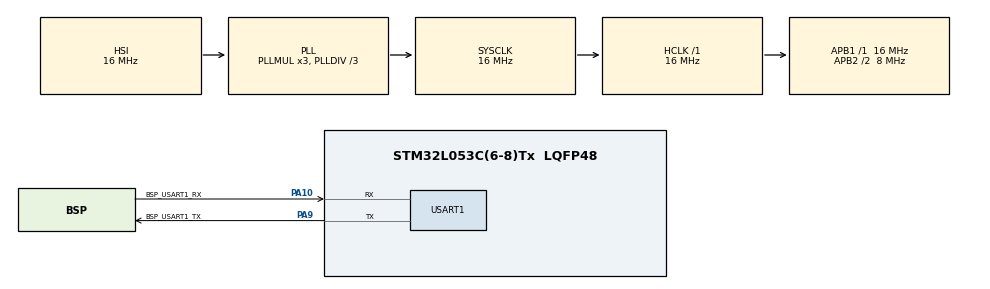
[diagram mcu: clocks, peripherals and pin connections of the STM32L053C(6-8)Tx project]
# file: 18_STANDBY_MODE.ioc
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Mcu.Family=STM32L0
Mcu.Name=STM32L053C(6-8)Tx
Mcu.Package=LQFP48
PA0.GPIO_Label=BSP_SYS_WKUP1
PA0.Mode=SYS_WakeUp0
PA0.Signal=SYS_WKUP1
PA10.GPIO_Label=BSP_USART1_RX
PA10.Mode=Asynchronous
PA10.Signal=USART1_RX
PA9.GPIO_Label=BSP_USART1_TX
PA9.Mode=Asynchronous
PA9.Signal=USART1_TX
ProjectManager.HeapSize=0x200
ProjectManager.StackSize=0x400
ProjectManager.TargetToolchain=STM32CubeIDE
RCC.AHBFreq_Value=16000000
RCC.APB1Freq_Value=16000000
RCC.APB1TimFreq_Value=16000000
RCC.APB2CLKDivider=RCC_HCLK_DIV2
RCC.APB2Freq_Value=8000000
RCC.APB2TimFreq_Value=16000000
RCC.HCLKFreq_Value=16000000
RCC.HSE_VALUE=8000000
RCC.HSI16_VALUE=16000000
RCC.HSI48MClockSelection=RCC_USBCLKSOURCE_HSI48
RCC.HSI48_VALUE=48000000
RCC.HSI_VALUE=16000000
RCC.LSE_VALUE=32768
RCC.MSI_VALUE=2097000
RCC.PLLDIV=RCC_PLLDIV_3
RCC.RTCClockSelection=RCC_RTCCLKSOURCE_LSI
RCC.RTCClockSelectionVirtual=RCC_RTCCLKSOURCE_LSE
RCC.SYSCLKFreq_VALUE=16000000
RCC.SYSCLKSource=RCC_SYSCLKSOURCE_PLLCLK
RCC.VCOOutputFreq_Value=48000000
USART1.VirtualMode-Asynchronous=VM_ASYNC
VP_RTC_VS_RTC_Activate.Mode=RTC_Enabled
VP_RTC_VS_RTC_WakeUp_intern.Mode=WakeUp
board=STM32L0538-DISCO

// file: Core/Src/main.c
/* USER CODE BEGIN Header */
/**
 ******************************************************************************
 * @file           : main.c
 * @brief          : Main program body
 ******************************************************************************
 * @attention
 *
 * Copyright (c) 2024 STMicroelectronics.
 * All rights reserved.
 *
 * This software is licensed under terms that can be found in the LICENSE file
 * in the root directory of this software component.
 * If no LICENSE file comes with this software, it is provided AS-IS.
 *
 ******************************************************************************
 */
/* USER CODE END Header */
#include "main.h"

/* USER CODE BEGIN Includes */
#include <string.h>
/* USER CODE END Includes */

RTC_HandleTypeDef hrtc;

UART_HandleTypeDef huart1;

/* USER CODE BEGIN PV */
int i;
/* USER CODE END PV */

void SystemClock_Config(void);
static void MX_GPIO_Init(void);
static void MX_USART1_UART_Init(void);
static void MX_RTC_Init(void);

int main(void)
{

  /* MCU Configuration--------------------------------------------------------*/

  /* Reset of all peripherals, Initializes the Flash interface and the Systick. */
  HAL_Init();

  /* Configure the system clock */
  SystemClock_Config();

  /* Initialize all configured peripherals */
  MX_GPIO_Init();
  MX_USART1_UART_Init();
  MX_RTC_Init();
  /* USER CODE BEGIN 2 */

	/* check if the SB flag is set */
	if (__HAL_PWR_GET_FLAG(PWR_FLAG_SB) != RESET) {
		__HAL_PWR_CLEAR_FLAG(PWR_FLAG_SB);		// clear the flag

		/* display the string */
		char *str = "Wake-up from the standby mode\r\n";
		HAL_UART_Transmit(&huart1, (uint8_t*) str, strlen(str), HAL_MAX_DELAY);

		/* blink led */
//		for (i = 0; i < 20; i++) {
//			HAL_GPIO_TogglePin(GPIOA, GPIO_PIN_5);
//			HAL_Delay(200);
//		}

				/* disable the wakeup pin */
		HAL_PWR_DisableWakeUpPin(PWR_WAKEUP_PIN1); // disable PA0

		/* deactivate RTC wakeup */
		HAL_RTCEx_DeactivateWakeUpTimer(&hrtc);

	}
	/** Now Enter the standby mode **/
	/* clear the wakeup flag */
	__HAL_PWR_CLEAR_FLAG(PWR_FLAG_WU);

	/* clear the RTC wake-up(WU) flag */
	__HAL_RTC_WAKEUPTIMER_CLEAR_FLAG(&hrtc, RTC_FLAG_WUTF);

	/* display the string */
	char *str1 = "About to enter the standby mode\r\n";
	HAL_UART_Transmit(&huart1, (uint8_t*) str1, strlen(str1), HAL_MAX_DELAY);

	/* blink led */
//	for (i = 0; i < 5; i++) {
//		HAL_GPIO_TogglePin(GPIOA, GPIO_PIN_5);
//		HAL_Delay(750);
//	}

	/* Enable the wakeup pin */
	HAL_PWR_EnableWakeUpPin(PWR_WAKEUP_PIN1);

	/* enable the RTC Wakeup */
	/*  RTC Wake-up Interrupt Generation:
	 Wake-up Time Base = (RTC_WAKEUPCLOCK_RTCCLK_DIV /(LSI))
	 ==> WakeUpCounter = Wake-up Time / Wake-up Time Base

	 To configure the wake up timer to 5s the WakeUpCounter is set to 0x2710:
	 RTC_WAKEUPCLOCK_RTCCLK_DIV = RTCCLK_Div16 = 16
	 Wake-up Time Base = 16 /(32KHz) = 0.0005 seconds
	 ==> WakeUpCounter = ~5s/0.0005s = 20000 = 0x2710

	 FOR 10 sec;
	 wakeup counter = 0x5A56
	 */
	if (HAL_RTCEx_SetWakeUpTimer_IT(&hrtc, 0x5A56, RTC_WAKEUPCLOCK_RTCCLK_DIV16)
			!= HAL_OK) {
		Error_Handler();
	}

	/* string to be sure */
	char *str2 = "standby mode is on\r\n";
	HAL_UART_Transmit(&huart1, (uint8_t*) str2, strlen(str2),
	HAL_MAX_DELAY);

	/* Deinitialize USART1 before entering standby mode */
	HAL_UART_DeInit(&huart1);

	/* Deinitialize GPIO before entering standby mode */
	HAL_GPIO_DeInit(GPIOA, GPIO_PIN_5); // Deinitialize GPIOA Pin 5

	/* enter the standby mode */
	HAL_PWR_EnterSTANDBYMode();

  /* USER CODE END 2 */

  /* Infinite loop */
	while (1) {

	}
}

void SystemClock_Config(void)
{
  RCC_OscInitTypeDef RCC_OscInitStruct = {0};
  RCC_ClkInitTypeDef RCC_ClkInitStruct = {0};
  RCC_PeriphCLKInitTypeDef PeriphClkInit = {0};

  /** Configure the main internal regulator output voltage
  */
  __HAL_PWR_VOLTAGESCALING_CONFIG(PWR_REGULATOR_VOLTAGE_SCALE1);

  /** Initializes the RCC Oscillators according to the specified parameters
  * in the RCC_OscInitTypeDef structure.
  */
  RCC_OscInitStruct.OscillatorType = RCC_OSCILLATORTYPE_HSI|RCC_OSCILLATORTYPE_LSI;
  RCC_OscInitStruct.HSIState = RCC_HSI_ON;
  RCC_OscInitStruct.HSICalibrationValue = RCC_HSICALIBRATION_DEFAULT;
  RCC_OscInitStruct.LSIState = RCC_LSI_ON;
  RCC_OscInitStruct.PLL.PLLState = RCC_PLL_ON;
  RCC_OscInitStruct.PLL.PLLSource = RCC_PLLSOURCE_HSI;
  RCC_OscInitStruct.PLL.PLLMUL = RCC_PLLMUL_3;
  RCC_OscInitStruct.PLL.PLLDIV = RCC_PLLDIV_3;
  if (HAL_RCC_OscConfig(&RCC_OscInitStruct) != HAL_OK)
  {
    Error_Handler();
  }

  /** Initializes the CPU, AHB and APB buses clocks
  */
  RCC_ClkInitStruct.ClockType = RCC_CLOCKTYPE_HCLK|RCC_CLOCKTYPE_SYSCLK
                              |RCC_CLOCKTYPE_PCLK1|RCC_CLOCKTYPE_PCLK2;
  RCC_ClkInitStruct.SYSCLKSource = RCC_SYSCLKSOURCE_PLLCLK;
  RCC_ClkInitStruct.AHBCLKDivider = RCC_SYSCLK_DIV1;
  RCC_ClkInitStruct.APB1CLKDivider = RCC_HCLK_DIV1;
  RCC_ClkInitStruct.APB2CLKDivider = RCC_HCLK_DIV2;

  if (HAL_RCC_ClockConfig(&RCC_ClkInitStruct, FLASH_LATENCY_0) != HAL_OK)
  {
    Error_Handler();
  }
  PeriphClkInit.PeriphClockSelection = RCC_PERIPHCLK_USART1|RCC_PERIPHCLK_RTC;
  PeriphClkInit.Usart1ClockSelection = RCC_USART1CLKSOURCE_PCLK2;
  PeriphClkInit.RTCClockSelection = RCC_RTCCLKSOURCE_LSI;
  if (HAL_RCCEx_PeriphCLKConfig(&PeriphClkInit) != HAL_OK)
  {
    Error_Handler();
  }
}

static void MX_RTC_Init(void)
{

  /** Initialize RTC Only
  */
  hrtc.Instance = RTC;
  hrtc.Init.HourFormat = RTC_HOURFORMAT_24;
  hrtc.Init.AsynchPrediv = 127;
  hrtc.Init.SynchPrediv = 255;
  hrtc.Init.OutPut = RTC_OUTPUT_DISABLE;
  hrtc.Init.OutPutRemap = RTC_OUTPUT_REMAP_NONE;
  hrtc.Init.OutPutPolarity = RTC_OUTPUT_POLARITY_HIGH;
  hrtc.Init.OutPutType = RTC_OUTPUT_TYPE_OPENDRAIN;
  if (HAL_RTC_Init(&hrtc) != HAL_OK)
  {
    Error_Handler();
  }

  /** Enable the WakeUp
  */
  if (HAL_RTCEx_SetWakeUpTimer(&hrtc, 0, RTC_WAKEUPCLOCK_RTCCLK_DIV16) != HAL_OK)
  {
    Error_Handler();
  }

}

static void MX_USART1_UART_Init(void)
{

  huart1.Instance = USART1;
  huart1.Init.BaudRate = 115200;
  huart1.Init.WordLength = UART_WORDLENGTH_8B;
  huart1.Init.StopBits = UART_STOPBITS_1;
  huart1.Init.Parity = UART_PARITY_NONE;
  huart1.Init.Mode = UART_MODE_TX_RX;
  huart1.Init.HwFlowCtl = UART_HWCONTROL_NONE;
  huart1.Init.OverSampling = UART_OVERSAMPLING_16;
  huart1.Init.OneBitSampling = UART_ONE_BIT_SAMPLE_DISABLE;
  huart1.AdvancedInit.AdvFeatureInit = UART_ADVFEATURE_NO_INIT;
  if (HAL_UART_Init(&huart1) != HAL_OK)
  {
    Error_Handler();
  }

}

static void MX_GPIO_Init(void)
{
  GPIO_InitTypeDef GPIO_InitStruct = {0};

  /* GPIO Ports Clock Enable */
  __HAL_RCC_GPIOC_CLK_ENABLE();
  __HAL_RCC_GPIOH_CLK_ENABLE();
  __HAL_RCC_GPIOA_CLK_ENABLE();
  __HAL_RCC_GPIOB_CLK_ENABLE();

  /*Configure GPIO pins : PC13 PC14 PC15 */
  GPIO_InitStruct.Pin = GPIO_PIN_13|GPIO_PIN_14|GPIO_PIN_15;
  GPIO_InitStruct.Mode = GPIO_MODE_ANALOG;
  GPIO_InitStruct.Pull = GPIO_NOPULL;
  HAL_GPIO_Init(GPIOC, &GPIO_InitStruct);

  /*Configure GPIO pins : PH0 PH1 */
  GPIO_InitStruct.Pin = GPIO_PIN_0|GPIO_PIN_1;
  GPIO_InitStruct.Mode = GPIO_MODE_ANALOG;
  GPIO_InitStruct.Pull = GPIO_NOPULL;
  HAL_GPIO_Init(GPIOH, &GPIO_InitStruct);

  /*Configure GPIO pins : PA1 PA2 PA3 PA4
                           PA5 PA6 PA7 PA8
                           PA11 PA12 PA13 PA14
                           PA15 */
  GPIO_InitStruct.Pin = GPIO_PIN_1|GPIO_PIN_2|GPIO_PIN_3|GPIO_PIN_4
                          |GPIO_PIN_5|GPIO_PIN_6|GPIO_PIN_7|GPIO_PIN_8
                          |GPIO_PIN_11|GPIO_PIN_12|GPIO_PIN_13|GPIO_PIN_14
                          |GPIO_PIN_15;
  GPIO_InitStruct.Mode = GPIO_MODE_ANALOG;
  GPIO_InitStruct.Pull = GPIO_NOPULL;
  HAL_GPIO_Init(GPIOA, &GPIO_InitStruct);

  /*Configure GPIO pins : PB0 PB1 PB2 PB10
                           PB11 PB12 PB13 PB14
                           PB15 PB3 PB4 PB5
                           PB6 PB7 PB8 PB9 */
  GPIO_InitStruct.Pin = GPIO_PIN_0|GPIO_PIN_1|GPIO_PIN_2|GPIO_PIN_10
                          |GPIO_PIN_11|GPIO_PIN_12|GPIO_PIN_13|GPIO_PIN_14
                          |GPIO_PIN_15|GPIO_PIN_3|GPIO_PIN_4|GPIO_PIN_5
                          |GPIO_PIN_6|GPIO_PIN_7|GPIO_PIN_8|GPIO_PIN_9;
  GPIO_InitStruct.Mode = GPIO_MODE_ANALOG;
  GPIO_InitStruct.Pull = GPIO_NOPULL;
  HAL_GPIO_Init(GPIOB, &GPIO_InitStruct);

}

void Error_Handler(void)
{
	__disable_irq();
	while (1) {
	}
}
